# STM32C031 register map
File version: 0.2
CPU: CM0 r0p0, little endian, MPU, FPU, 4 interrupt priority bits
Registers are 32-bit, read-write, reset 0x0 unless marked. A register's access mark holds for its fields unless they carry their own. Offsets are from the block's base; [hi:lo] are bit positions; {n}, {i} and the like mark numbered series.

## DMAMUX — DMAMUX register block
Base 0x40020800
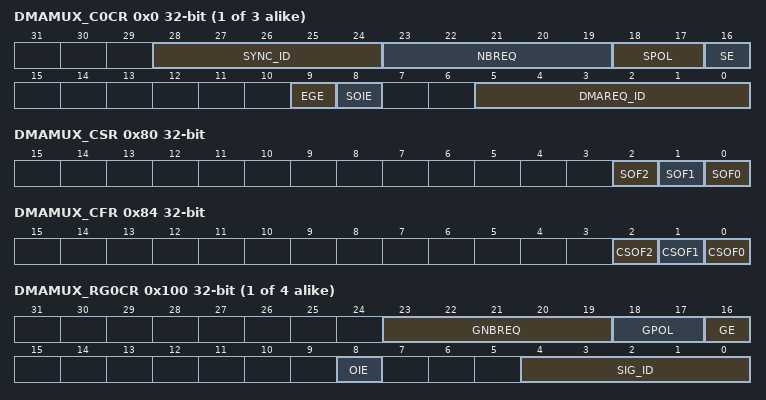
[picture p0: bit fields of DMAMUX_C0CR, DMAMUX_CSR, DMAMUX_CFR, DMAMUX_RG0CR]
{0x0+4i} DMAMUX_C{i}CR (i=0..2) — DMAMUX request line multiplexer channel {i} configuration register
  [28:24] SYNC_ID — Synchronization identification Selects the synchronization input (see inputs to resources).
  [23:19] NBREQ — Number of DMA requests minus 1 to forward Defines the number of DMA requests to forward to the DMA controller after a synchronization event, and/or the number of DMA requests before an output event is generated. This field shall only be written when both SE and EGE bits are low.
  [18:17] SPOL — Synchronization polarity Defines the edge polarity of the selected synchronization input:
    0=No event, i.e. no synchronization nor detection.; 1=Rising edge; 2=Falling edge; 3=Rising and falling edges
  [16] SE — Synchronization enable
    0=Synchronization disabled; 1=Synchronization enabled
  [9] EGE — Event generation enable
    0=Event generation disabled; 1=Event generation enabled
  [8] SOIE — Synchronization overrun interrupt enable
    0=Interrupt disabled; 1=Interrupt enabled
  [5:0] DMAREQ_ID — DMA request identification Selects the input DMA request. See the DMAMUX table about assignments of multiplexer inputs to resources.
0x80 DMAMUX_CSR ro — DMAMUX request line multiplexer interrupt channel status register
  [2] SOF2 — Synchronization overrun event flag The flag is set when a synchronization event occurs on a DMA request line multiplexer channel x, while the DMA request counter value is lower than NBREQ. The flag is cleared by writing 1 to the corresponding CSOFx bit in DMAMUX_CFR register.
  [1] SOF1 — Synchronization overrun event flag The flag is set when a synchronization event occurs on a DMA request line multiplexer channel x, while the DMA request counter value is lower than NBREQ. The flag is cleared by writing 1 to the corresponding CSOFx bit in DMAMUX_CFR register.
  [0] SOF0 — Synchronization overrun event flag The flag is set when a synchronization event occurs on a DMA request line multiplexer channel x, while the DMA request counter value is lower than NBREQ. The flag is cleared by writing 1 to the corresponding CSOFx bit in DMAMUX_CFR register.
0x84 DMAMUX_CFR wo — DMAMUX request line multiplexer interrupt clear flag register
  [2] CSOF2 — Clear synchronization overrun event flag Writing 1 in each bit clears the corresponding overrun flag SOFx in the DMAMUX_CSR register.
  [1] CSOF1 — Clear synchronization overrun event flag Writing 1 in each bit clears the corresponding overrun flag SOFx in the DMAMUX_CSR register.
  [0] CSOF0 — Clear synchronization overrun event flag Writing 1 in each bit clears the corresponding overrun flag SOFx in the DMAMUX_CSR register.
{0x100+4i} DMAMUX_RG{i}CR (i=0..3) — DMAMUX request generator channel {i} configuration register
  [23:19] GNBREQ — Number of DMA requests to be generated (minus 1) Defines the number of DMA requests to be generated after a trigger event. The actual number of generated DMA requests is GNBREQ +1. Note: This field must be written only when GE bit is disabled.
  [18:17] GPOL — DMA request generator trigger polarity Defines the edge polarity of the selected trigger input
    0=No event, i.e. no trigger detection nor generation.; 1=Rising edge; 2=Falling edge; 3=Rising and falling edges
  [16] GE — DMA request generator channel x enable
    0=DMA request generator channel x disabled; 1=DMA request generator channel x enabled
  [8] OIE — Trigger overrun interrupt enable
    0=Interrupt on a trigger overrun event occurrence is disabled; 1=Interrupt on a trigger overrun event occurrence is enabled
  [4:0] SIG_ID — Signal identification Selects the DMA request trigger input used for the channel x of the DMA request generator
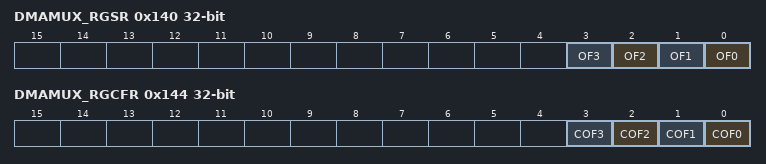
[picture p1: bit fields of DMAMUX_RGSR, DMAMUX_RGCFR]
0x140 DMAMUX_RGSR ro — DMAMUX request generator interrupt status register
  [n] OF{n} (n=0..3) — Trigger overrun event flag The flag is set when a new trigger event occurs on DMA request generator channel x, before the request counter underrun (the internal request counter programmed via the GNBREQ field of the DMAMUX_RGxCR register). The flag is cleared by writing 1 to the corresponding COFx bit in the DMAMUX_RGCFR register.
0x144 DMAMUX_RGCFR wo — DMAMUX request generator interrupt clear flag register
  [n] COF{n} (n=0..3) — Clear trigger overrun event flag Writing 1 in each bit clears the corresponding overrun flag OFx in the DMAMUX_RGSR register.
